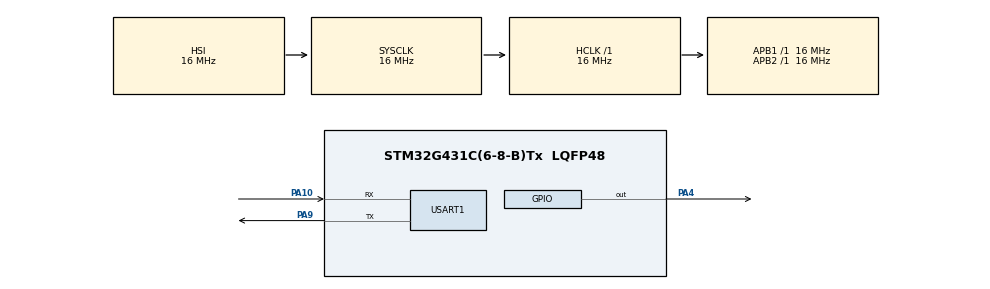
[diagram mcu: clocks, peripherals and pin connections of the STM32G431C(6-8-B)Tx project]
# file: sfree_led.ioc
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FREERTOS.Tasks01=LTask,24,128,StartLTask,Default,NULL,Dynamic,NULL,NULL;STask,8,128,StartSTask,Default,NULL,Dynamic,NULL,NULL
Mcu.Family=STM32G4
Mcu.Name=STM32G431C(6-8-B)Tx
Mcu.Package=LQFP48
NVIC.PriorityGroup=NVIC_PRIORITYGROUP_4
NVIC.TIM4_IRQn=true\:15\:0\:false\:false\:true\:false\:false\:true\:true
NVIC.TimeBase=TIM4_IRQn
NVIC.TimeBaseIP=TIM4
PA10.Mode=Asynchronous
PA10.Signal=USART1_RX
PA13.Mode=Serial_Wire
PA13.Signal=SYS_JTMS-SWDIO
PA14.Mode=Serial_Wire
PA14.Signal=SYS_JTCK-SWCLK
PA4.GPIO_PuPd=GPIO_PULLDOWN
PA4.Signal=GPIO_Output
PA9.Mode=Asynchronous
PA9.Signal=USART1_TX
ProjectManager.HeapSize=0x200
ProjectManager.StackSize=0x400
ProjectManager.TargetToolchain=CMake
RCC.AHBFreq_Value=16000000
RCC.APB1Freq_Value=16000000
RCC.APB1TimFreq_Value=16000000
RCC.APB2Freq_Value=16000000
RCC.APB2TimFreq_Value=16000000
RCC.CortexFreq_Value=16000000
RCC.EXTERNAL_CLOCK_VALUE=12288000
RCC.HCLKFreq_Value=16000000
RCC.HSE_VALUE=8000000
RCC.HSI48_VALUE=48000000
RCC.HSI_VALUE=16000000
RCC.LSE_VALUE=32768
RCC.SYSCLKFreq_VALUE=16000000
RCC.USBFreq_Value=64000000
RCC.VCOOutputFreq_Value=128000000
USART1.VirtualMode-Asynchronous=VM_ASYNC
VP_FREERTOS_VS_CMSIS_V2.Mode=CMSIS_V2
VP_SYS_VS_DBSignals.Mode=DisableDeadBatterySignals
VP_SYS_VS_tim4.Mode=TIM4
board=custom

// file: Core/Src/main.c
/* USER CODE BEGIN Header */
/**
  ******************************************************************************
  * @file           : main.c
  * @brief          : Main program body
  ******************************************************************************
  * @attention
  *
  * Copyright (c) 2025 STMicroelectronics.
  * All rights reserved.
  *
  * This software is licensed under terms that can be found in the LICENSE file
  * in the root directory of this software component.
  * If no LICENSE file comes with this software, it is provided AS-IS.
  *
  ******************************************************************************
  */
/* USER CODE END Header */
#include "main.h"
#include "cmsis_os.h"

UART_HandleTypeDef huart1;

/* Definitions for LTask */
osThreadId_t LTaskHandle;
const osThreadAttr_t LTask_attributes = {
  .name = "LTask",
  .priority = (osPriority_t) osPriorityNormal,
  .stack_size = 128 * 4
};
/* Definitions for STask */
osThreadId_t STaskHandle;
const osThreadAttr_t STask_attributes = {
  .name = "STask",
  .priority = (osPriority_t) osPriorityLow,
  .stack_size = 128 * 4
};

void SystemClock_Config(void);
static void MX_GPIO_Init(void);
static void MX_USART1_UART_Init(void);
void StartLTask(void *argument);
void StartSTask(void *argument);

int main(void)
{

  /* MCU Configuration--------------------------------------------------------*/

  /* Reset of all peripherals, Initializes the Flash interface and the Systick. */
  HAL_Init();

  /* Configure the system clock */
  SystemClock_Config();

  /* Initialize all configured peripherals */
  MX_GPIO_Init();
  MX_USART1_UART_Init();

  /* Init scheduler */
  osKernelInitialize();

  /* Create the thread(s) */
  /* creation of LTask */
  LTaskHandle = osThreadNew(StartLTask, NULL, &LTask_attributes);

  /* creation of STask */
  STaskHandle = osThreadNew(StartSTask, NULL, &STask_attributes);

  /* Start scheduler */
  osKernelStart();

  /* We should never get here as control is now taken by the scheduler */

  /* Infinite loop */
  while (1)
  {

  }
}

void SystemClock_Config(void)
{
  RCC_OscInitTypeDef RCC_OscInitStruct = {0};
  RCC_ClkInitTypeDef RCC_ClkInitStruct = {0};

  /** Configure the main internal regulator output voltage
  */
  HAL_PWREx_ControlVoltageScaling(PWR_REGULATOR_VOLTAGE_SCALE1);

  /** Initializes the RCC Oscillators according to the specified parameters
  * in the RCC_OscInitTypeDef structure.
  */
  RCC_OscInitStruct.OscillatorType = RCC_OSCILLATORTYPE_HSI;
  RCC_OscInitStruct.HSIState = RCC_HSI_ON;
  RCC_OscInitStruct.HSICalibrationValue = RCC_HSICALIBRATION_DEFAULT;
  RCC_OscInitStruct.PLL.PLLState = RCC_PLL_NONE;
  if (HAL_RCC_OscConfig(&RCC_OscInitStruct) != HAL_OK)
  {
    Error_Handler();
  }

  /** Initializes the CPU, AHB and APB buses clocks
  */
  RCC_ClkInitStruct.ClockType = RCC_CLOCKTYPE_HCLK|RCC_CLOCKTYPE_SYSCLK
                              |RCC_CLOCKTYPE_PCLK1|RCC_CLOCKTYPE_PCLK2;
  RCC_ClkInitStruct.SYSCLKSource = RCC_SYSCLKSOURCE_HSI;
  RCC_ClkInitStruct.AHBCLKDivider = RCC_SYSCLK_DIV1;
  RCC_ClkInitStruct.APB1CLKDivider = RCC_HCLK_DIV1;
  RCC_ClkInitStruct.APB2CLKDivider = RCC_HCLK_DIV1;

  if (HAL_RCC_ClockConfig(&RCC_ClkInitStruct, FLASH_LATENCY_0) != HAL_OK)
  {
    Error_Handler();
  }
}

static void MX_USART1_UART_Init(void)
{

  huart1.Instance = USART1;
  huart1.Init.BaudRate = 115200;
  huart1.Init.WordLength = UART_WORDLENGTH_8B;
  huart1.Init.StopBits = UART_STOPBITS_1;
  huart1.Init.Parity = UART_PARITY_NONE;
  huart1.Init.Mode = UART_MODE_TX_RX;
  huart1.Init.HwFlowCtl = UART_HWCONTROL_NONE;
  huart1.Init.OverSampling = UART_OVERSAMPLING_16;
  huart1.Init.OneBitSampling = UART_ONE_BIT_SAMPLE_DISABLE;
  huart1.Init.ClockPrescaler = UART_PRESCALER_DIV1;
  huart1.AdvancedInit.AdvFeatureInit = UART_ADVFEATURE_NO_INIT;
  if (HAL_UART_Init(&huart1) != HAL_OK)
  {
    Error_Handler();
  }
  if (HAL_UARTEx_SetTxFifoThreshold(&huart1, UART_TXFIFO_THRESHOLD_1_8) != HAL_OK)
  {
    Error_Handler();
  }
  if (HAL_UARTEx_SetRxFifoThreshold(&huart1, UART_RXFIFO_THRESHOLD_1_8) != HAL_OK)
  {
    Error_Handler();
  }
  if (HAL_UARTEx_DisableFifoMode(&huart1) != HAL_OK)
  {
    Error_Handler();
  }

}

static void MX_GPIO_Init(void)
{
  GPIO_InitTypeDef GPIO_InitStruct = {0};

  /* GPIO Ports Clock Enable */
  __HAL_RCC_GPIOA_CLK_ENABLE();

  /*Configure GPIO pin Output Level */
  HAL_GPIO_WritePin(GPIOA, GPIO_PIN_4, GPIO_PIN_RESET);

  /*Configure GPIO pin : PA4 */
  GPIO_InitStruct.Pin = GPIO_PIN_4;
  GPIO_InitStruct.Mode = GPIO_MODE_OUTPUT_PP;
  GPIO_InitStruct.Pull = GPIO_PULLDOWN;
  GPIO_InitStruct.Speed = GPIO_SPEED_FREQ_LOW;
  HAL_GPIO_Init(GPIOA, &GPIO_InitStruct);

  /* USER CODE BEGIN MX_GPIO_Init_2 */
  // 添加USART1引脚配置
  GPIO_InitStruct.Pin = GPIO_PIN_9 | GPIO_PIN_10;
  GPIO_InitStruct.Mode = GPIO_MODE_AF_PP;
  GPIO_InitStruct.Pull = GPIO_NOPULL;
  GPIO_InitStruct.Speed = GPIO_SPEED_FREQ_LOW;
  GPIO_InitStruct.Alternate = GPIO_AF7_USART1;
  HAL_GPIO_Init(GPIOA, &GPIO_InitStruct);
  /* USER CODE END MX_GPIO_Init_2 */
}

void StartLTask(void *argument)
{
  /* USER CODE BEGIN 5 */
  /* Infinite loop */
  for(;;)
  {
    HAL_GPIO_TogglePin(GPIOA, GPIO_PIN_4);
    osDelay(500);
  }
  /* USER CODE END 5 */
}

void StartSTask(void *argument)
{
  /* USER CODE BEGIN StartSTask */
  char msg[] = "Hello World/n";
  /* Infinite loop */
  for(;;)
  {
    HAL_UART_Transmit(&huart1, (uint8_t *)msg, sizeof(msg)-1, HAL_MAX_DELAY);
    osDelay(200);
  }
  /* USER CODE END StartSTask */
}

void HAL_TIM_PeriodElapsedCallback(TIM_HandleTypeDef *htim)
{
  if (htim->Instance == TIM4)
  {
    HAL_IncTick();
  }
}

void Error_Handler(void)
{
  __disable_irq();
  while (1)
  {
  }
}
